# NUC029AN_v1 register map
File version: 1.0
Registers are 32-bit, read-write, reset 0x0 unless marked. A register's access mark holds for its fields unless they carry their own. Offsets are from the block's base; [hi:lo] are bit positions; 'fields as' and 'values as' point back to an identical list.

## TMR01 — TMR Register Map
Base 0x40010000
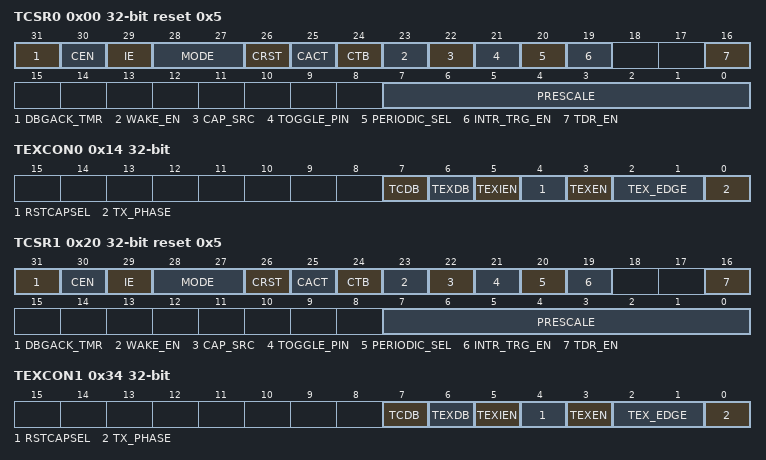
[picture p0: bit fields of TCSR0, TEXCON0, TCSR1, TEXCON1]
0x00 TCSR0 reset 0x5 — Timer0 Control and Status Register
  [31] DBGACK_TMR — ICE debug mode acknowledge Disable (write-protected). TIMER counter will keep going no matter ICE debug mode acknowledged or not.
    0=ICE debug mode acknowledgement effects TIMER counting; 1=ICE debug mode acknowledgement disabled
  [30] CEN — Timer Enable Bit
    0=Stops/Suspends counting; 1=Starts counting
  [29] IE — Interrupt Enable Bit. If timer interrupt is enabled, the timer asserts its interrupt signal when the associated timer is equal to TCMPR.
    0=Disable timer Interrupt; 1=Enable timer Interrupt
  [28:27] MODE — Timer Operating Mode
  [26] CRST — Timer Reset Bit. Set this bit will reset the 24-bit up-timer, 8-bit pre-scale counter and also force CEN to 0.
    0=No effect; 1=Reset Timer's pre-scaled counter, internal 24-bit up-timer and CEN bit
  [25] CACT ro — Timer Active Status Bit (Read only). This bit indicates the up-timer status.
    0=Timer is not active; 1=Timer is in active
  [24] CTB — Counter Mode Enable Bit. This bit is the counter mode enable bit. When Timer is used as an event counter, this bit should be set to 1 and Timer will work as an event counter. The counter detect phase can be selected as rising/falling edge of external pin by TX_PHASE field.
    0=Disable counter mode; 1=Enable counter mode
  [23] WAKE_EN — Wake up Enable. When WAKE_EN is set and the TIF is set, the timer controller will generator a wake-up trigger event to CPU.
    0=Wake-up trigger event disable; 1=Wake-up trigger event enable
  [22] CAP_SRC — Capture Function Source
    0=Capture Function source is from TxEX (Timer External Pin); 1=Capture Function source is from ACMP(Analog Comparator Output)
  [21] TOGGLE_PIN — Toggle Mode Output PIN
    0=Toggle mode output to Tx (Timer Event Count Pin); 1=Toggle mode output to TxEX (Timer External Pin)
  [20] PERIODIC_SEL — Periodic Mode Behavior Selection Enable. When users update TCMP, TDR will be reset to default value.
    0=The behavior selection in periodic mode is disabled; 1=The behavior selection in periodic mode is enabled
  [19] INTR_TRG_EN — Inter-Timer Trigger Mode Enable. This bit controls if the inter-timer trigger mode is enabled. If inter-timer trigger mode is enabled, the TIMER0/TIMER2 will be in counter mode and counting with external clock source or event. And, TIMER1/TIMER3 will be in trigger-counting mode of capture function. Note: For TIMER1 and TIMER3, this bit is ignored and the read back value is always 1'b0.
    0=The inter-timer trigger mode is disabled; 1=The inter-timer trigger mode is enabled
  [16] TDR_EN — Data Load Enable. When TDR_EN is set, TDR (Timer Data Register) will be updated continuously with the 24-bit up-timer value as the timer is counting.
    0=Timer Data Register update disable; 1=Timer Data Register update enable
  [7:0] PRESCALE — Pre-scale Counter
0x04 TCMPR0 — Timer0 Compare Register
  [23:0] TCMP — Timer Compared Value. Note1: Never write 0x0 or 0x1 in TCMP, or the core will run into unknown state. Note2: When timer is operating at continuous counting mode, the 24-bit up-timer will count continuously if software writes a new value into TCMP. If timer is operating at other modes, the 24-bit up-timer will restart counting and using newest TCMP value to be the compared value if software writes a new value into TCMP.
0x08 TISR0 — Timer0 Interrupt Status Register
  [0] TIF — Timer Interrupt Flag. This bit indicates the interrupt status of Timer. TIF bit is set by hardware when the up counting value of internal 24-bit timer matches the timer compared value (TCMP). It is cleared by writing 1 to this bit.
0x0C TDR0 ro — Timer0 Data Register
  [23:0] TDR — Timer Data Register. User can read TDR for getting current 24- bits up event counter value if TCSR[24] is 1
0x10 TCAP0 ro — Timer0 Capture Data Register
  [23:0] TCAP — Timer Capture Data Register. When TEXEN (TEXCON[3]) is set, RSTCAPSEL (TTXCON[4]) is 0, and the transition on the TEX pins associated TEX_EDGE(TEXCON[2:1]) setting is occurred, the internal 24-bit up-timer value will be loaded into TCAP. User can read this register for the counter value.
0x14 TEXCON0 — Timer0 External Control Register
  [7] TCDB — Timer Counter pin De-bounce enable bit. If this bit is enabled, the edge of T0~T3 pin is detected with de-bounce circuit.
    0=Disable De-bounce; 1=Enable De-bounce
  [6] TEXDB — Timer External Capture pin De-bounce enable bit. If this bit is enabled, the edge of T0EX~T3EX pin is detected with de-bounce circuit.
    0=Disable De-bounce; 1=Enable De-bounce
  [5] TEXIEN — Timer External interrupt Enable Bit
    0=Disable timer External Interrupt; 1=Enable timer External Interrupt
  [4] RSTCAPSEL — Timer External Reset Counter / Capture mode select
    0=TEX transition is using as the timer capture function; 1=TEX transition is using as the timer counter reset function
  [3] TEXEN — Timer External Pin Enable. This bit enables the reset/capture function on the TEX pin.
    0=The TEX pin will be ignored; 1=The transition detected on the TEX pin will result in capture or reset of timer counter
  [2:1] TEX_EDGE — Timer External Pin Edge Detect
    0=a 1 to 0 transition on TEX will be detected; 1=a 0 to 1 transition on TEX will be detected; 2=either 1 to 0 or 0 to 1 transition on TEX will be detected
  [0] TX_PHASE — Timer External Count Phase. This bit indicates the external count pin phase.
    0=A falling edge of external count pin will be counted; 1=A rising edge of external count pin will be counted
0x18 TEXISR0 — Timer0 External Interrupt Status Register
  [0] TEXIF — Timer External Interrupt Flag. This bit indicates the external interrupt status of Timer. This bit is set by hardware when TEXEN (TEXCON[3]) is to 1,and the transition on the TEX pins associated TEX_EDGE(TEXCON[2:1]) setting is occurred. It is cleared by writing 1 to this bit.
0x20 TCSR1 reset 0x5 — Timer1 Control and Status Register
  fields as TCSR0
0x24 TCMPR1 — Timer1 Compare Register
  fields as TCMPR0
0x28 TISR1 — Timer1 Interrupt Status Register
  fields as TISR0
0x2C TDR1 ro — Timer1 Data Register
  fields as TDR0
0x30 TCAP1 ro — Timer1 Capture Data Register
  fields as TCAP0
0x34 TEXCON1 — Timer1 External Control Register
  fields as TEXCON0
0x38 TEXISR1 — Timer1 External Interrupt Status Register
  fields as TEXISR0
